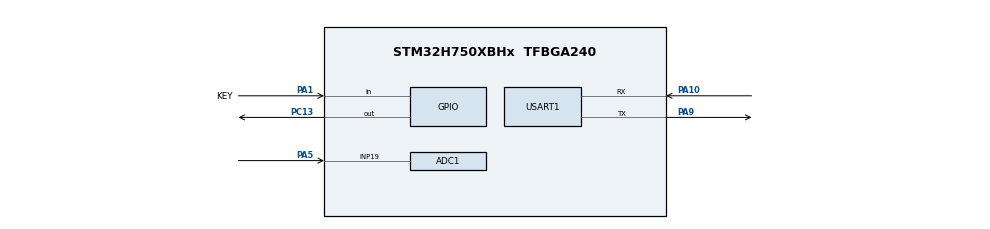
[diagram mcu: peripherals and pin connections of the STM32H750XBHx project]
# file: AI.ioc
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ADC1.Channel-4\#ChannelRegularConversion=ADC_CHANNEL_19
ADC1.NbrOfConversionFlag=1
ADC1.OffsetNumber-4\#ChannelRegularConversion=ADC_OFFSET_NONE
ADC1.OffsetSignedSaturation-4\#ChannelRegularConversion=DISABLE
ADC1.Rank-4\#ChannelRegularConversion=1
ADC1.SamplingTime-4\#ChannelRegularConversion=ADC_SAMPLETIME_1CYCLE_5
ADC1.master=1
CORTEX_M7.CPU_DCache=Enabled
CORTEX_M7.CPU_ICache=Enabled
CORTEX_M7.default_mode_Activation=1
Mcu.Family=STM32H7
Mcu.Name=STM32H750XBHx
Mcu.Package=TFBGA240
NVIC.PriorityGroup=NVIC_PRIORITYGROUP_4
PA1.GPIO_Label=KEY
PA1.GPIO_PuPd=GPIO_PULLDOWN
PA1.Signal=GPIO_Input
PA10.Mode=Asynchronous
PA10.Signal=USART1_RX
PA5.Signal=ADCx_INP19
PA9.GPIO_Speed=GPIO_SPEED_FREQ_HIGH
PA9.Mode=Asynchronous
PA9.Signal=USART1_TX
PC13.Signal=GPIO_Output
PH0-OSC_IN\ (PH0).Mode=HSE-External-Clock-Source
PH0-OSC_IN\ (PH0).Signal=RCC_OSC_IN
ProjectManager.HeapSize=0x4000
ProjectManager.StackSize=0x4000
ProjectManager.TargetToolchain=MDK-ARM V5.32
RCC.ADCCLockSelection=RCC_ADCCLKSOURCE_PLL3
RCC.ADCFreq_Value=32000000
RCC.APB1Freq_Value=120000000
RCC.APB2Freq_Value=120000000
RCC.APB3Freq_Value=120000000
RCC.APB4Freq_Value=120000000
RCC.CortexFreq_Value=480000000
RCC.D1PPRE=RCC_APB3_DIV2
RCC.D2PPRE1=RCC_APB1_DIV2
RCC.D2PPRE2=RCC_APB2_DIV2
RCC.D3PPRE=RCC_APB4_DIV2
RCC.DIVM1=4
RCC.DIVM2=1
RCC.DIVM3=1
RCC.DIVN1=480
RCC.DIVN2=19
RCC.DIVN3=20
RCC.DIVR3=5
RCC.HCLKFreq_Value=240000000
RCC.HPRE=RCC_HCLK_DIV2
RCC.HSE_VALUE=8000000
RCC.PLL3FRACN=0
RCC.PLLFRACN=0
RCC.PLLSourceVirtual=RCC_PLLSOURCE_HSE
RCC.SYSCLKFreq_VALUE=480000000
RCC.SYSCLKSource=RCC_SYSCLKSOURCE_PLLCLK
RCC.USBFreq_Value=480000000
SH.ADCx_INP19.0=ADC1_INP19,IN19-Single-Ended
STMicroelectronics.X-CUBE-AI.10.2.0.ActivationBufferSizeList=4752
STMicroelectronics.X-CUBE-AI.10.2.0.ActivationBuffers=pool0
STMicroelectronics.X-CUBE-AI.10.2.0.ActivationNames=pool0
STMicroelectronics.X-CUBE-AI.10.2.0.ActivationSizes=AI_NETWORK_DATA_ACTIVATION_1_SIZE
STMicroelectronics.X-CUBE-AI.10.2.0.ApplicationCcDeviceJjApplication=ApplicationTemplate
STMicroelectronics.X-CUBE-AI.10.2.0.HeapSize=0x4000
STMicroelectronics.X-CUBE-AI.10.2.0.InternalRamActivationBufferMaxSize=AI_NETWORK_DATA_ACTIVATIONS_SIZE
STMicroelectronics.X-CUBE-AI.10.2.0.LatestDirectoryUsed-3641962debb2109bb404ed91b162e236a1cb7b712d591e769295285bf5952ec8=D\:\\ONEDREIVE\\OneDrive\\Desktop\\Inbox
STMicroelectronics.X-CUBE-AI.10.2.0.MaximumNumberOfInputLayer=1
STMicroelectronics.X-CUBE-AI.10.2.0.MaximumNumberOfOutputLayer=1
STMicroelectronics.X-CUBE-AI.10.2.0.MaximumSizeOfInputLayer=1
STMicroelectronics.X-CUBE-AI.10.2.0.MaximumSizeOfOutputLayer=1
STMicroelectronics.X-CUBE-AI.10.2.0.ModelActualCompression-3641962debb2109bb404ed91b162e236a1cb7b712d591e769295285bf5952ec8=0.0
STMicroelectronics.X-CUBE-AI.10.2.0.ModelCompression-3641962debb2109bb404ed91b162e236a1cb7b712d591e769295285bf5952ec8=None
STMicroelectronics.X-CUBE-AI.10.2.0.ModelFlashOccupation-3641962debb2109bb404ed91b162e236a1cb7b712d591e769295285bf5952ec8=61936
STMicroelectronics.X-CUBE-AI.10.2.0.ModelHashList=3641962debb2109bb404ed91b162e236a1cb7b712d591e769295285bf5952ec8
STMicroelectronics.X-CUBE-AI.10.2.0.ModelKind-3641962debb2109bb404ed91b162e236a1cb7b712d591e769295285bf5952ec8=TFLITE
STMicroelectronics.X-CUBE-AI.10.2.0.ModelMacc-3641962debb2109bb404ed91b162e236a1cb7b712d591e769295285bf5952ec8=12896
STMicroelectronics.X-CUBE-AI.10.2.0.ModelName-3641962debb2109bb404ed91b162e236a1cb7b712d591e769295285bf5952ec8=network
STMicroelectronics.X-CUBE-AI.10.2.0.ModelNameList=network
STMicroelectronics.X-CUBE-AI.10.2.0.ModelRamOccupation-3641962debb2109bb404ed91b162e236a1cb7b712d591e769295285bf5952ec8=4752
STMicroelectronics.X-CUBE-AI.10.2.0.ModelStructureFile-3641962debb2109bb404ed91b162e236a1cb7b712d591e769295285bf5952ec8=D\:\\ONEDREIVE\\OneDrive\\Desktop\\Inbox\\mnist_simple_model.tflite
STMicroelectronics.X-CUBE-AI.10.2.0.ModelType-3641962debb2109bb404ed91b162e236a1cb7b712d591e769295285bf5952ec8=STM32Cube.AI MCU runtime
STMicroelectronics.X-CUBE-AI.10.2.0.ReadyForCodeGeneration=true
STMicroelectronics.X-CUBE-AI.10.2.0.StackSize=0x4000
STMicroelectronics.X-CUBE-AI.10.2.0.WorkingBufferStartAddrList=0xFFFFFFFF
STMicroelectronics.X-CUBE-AI.10.2.0.XAaCUBEAaAICcArtificialOoIntelligenceJjCore=true
STMicroelectronics.X-CUBE-AI.10.2.0.copyWeightToRam=false
STMicroelectronics.X-CUBE-AI.10.2.0.copyWeightToRam-3641962debb2109bb404ed91b162e236a1cb7b712d591e769295285bf5952ec8=false
STMicroelectronics.X-CUBE-AI.10.2.0.customLayerConfigEnabled=false
STMicroelectronics.X-CUBE-AI.10.2.0.customLayerConfigEnabled-3641962debb2109bb404ed91b162e236a1cb7b712d591e769295285bf5952ec8=false
STMicroelectronics.X-CUBE-AI.10.2.0.noOnnxIoTranspose=false
STMicroelectronics.X-CUBE-AI.10.2.0.noOnnxIoTranspose-3641962debb2109bb404ed91b162e236a1cb7b712d591e769295285bf5952ec8=false
STMicroelectronics.X-CUBE-AI.10.2.0.useInputAllocation=true
STMicroelectronics.X-CUBE-AI.10.2.0.useInputAllocation-3641962debb2109bb404ed91b162e236a1cb7b712d591e769295285bf5952ec8=true
STMicroelectronics.X-CUBE-AI.10.2.0.useOutputAllocation=true
STMicroelectronics.X-CUBE-AI.10.2.0.useOutputAllocation-3641962debb2109bb404ed91b162e236a1cb7b712d591e769295285bf5952ec8=true
USART1.VirtualMode-Asynchronous=VM_ASYNC
VP_CRC_VS_CRC.Mode=CRC_Activate
VP_MEMORYMAP_VS_MEMORYMAP.Mode=CurAppReg
VP_STMicroelectronics.X-CUBE-AI_VS_ArtificialOoIntelligenceJjXAaCUBEAaAI_10.2.0.Mode=ArtificialOoIntelligenceJjXAaCUBEAaAI
VP_STMicroelectronics.X-CUBE-AI_VS_DeviceJjApplication_10.2.0.Mode=DeviceJjApplication
board=custom

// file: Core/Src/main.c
/* USER CODE BEGIN Header */
/**
  ******************************************************************************
  * @file           : main.c
  * @brief          : Main program body
  ******************************************************************************
  * @attention
  *
  * Copyright (c) 2026 STMicroelectronics.
  * All rights reserved.
  *
  * This software is licensed under terms that can be found in the LICENSE file
  * in the root directory of this software component.
  * If no LICENSE file comes with this software, it is provided AS-IS.
  *
  ******************************************************************************
  */
/* USER CODE END Header */
#include "main.h"
#include "adc.h"
#include "crc.h"
#include "memorymap.h"
#include "usart.h"
#include "gpio.h"
#include "app_x-cube-ai.h"

/* USER CODE BEGIN Includes */

#include <stdio.h>
/* USER CODE END Includes */

/* USER CODE BEGIN PTD */
#define LED_PIN GPIO_PIN_13
#define LED_GPIO_PORT GPIOC
#define LED_ON  HAL_GPIO_WritePin(LED_GPIO_PORT, LED_PIN, GPIO_PIN_RESET)  // 低电平点亮（根据硬件调整）
#define LED_OFF HAL_GPIO_WritePin(LED_GPIO_PORT, LED_PIN, GPIO_PIN_SET)    // 高电平熄灭
/* USER CODE END PTD */

/* USER CODE BEGIN PV */
int fputc(int ch, FILE *f) {
    extern UART_HandleTypeDef huart1;
    HAL_UART_Transmit(&huart1, (uint8_t *)&ch, 1, 0xFFFF);
    return ch;
}
/* USER CODE END PV */

void SystemClock_Config(void);
static void MPU_Config(void);

int main(void)
{

  /* MPU Configuration--------------------------------------------------------*/
  MPU_Config();

  /* Enable the CPU Cache */

  /* Enable I-Cache---------------------------------------------------------*/
  SCB_EnableICache();

  /* Enable D-Cache---------------------------------------------------------*/
  SCB_EnableDCache();

  /* MCU Configuration--------------------------------------------------------*/

  /* Reset of all peripherals, Initializes the Flash interface and the Systick. */
  HAL_Init();

  /* Configure the system clock */
  SystemClock_Config();

  /* Initialize all configured peripherals */
  MX_GPIO_Init();
  MX_ADC1_Init();
  MX_USART1_UART_Init();
  MX_CRC_Init();
  MX_X_CUBE_AI_Init();
  /* USER CODE BEGIN 2 */
HAL_GPIO_WritePin(GPIOC, GPIO_PIN_13, GPIO_PIN_RESET);
  /* USER CODE END 2 */

  /* Infinite loop */
  while (1)
  {

MX_X_CUBE_AI_Process();

  }
}

void SystemClock_Config(void)
{
  RCC_OscInitTypeDef RCC_OscInitStruct = {0};
  RCC_ClkInitTypeDef RCC_ClkInitStruct = {0};

  /** Supply configuration update enable
  */
  HAL_PWREx_ConfigSupply(PWR_LDO_SUPPLY);

  /** Configure the main internal regulator output voltage
  */
  __HAL_PWR_VOLTAGESCALING_CONFIG(PWR_REGULATOR_VOLTAGE_SCALE0);

  while(!__HAL_PWR_GET_FLAG(PWR_FLAG_VOSRDY)) {}

  /** Initializes the RCC Oscillators according to the specified parameters
  * in the RCC_OscInitTypeDef structure.
  */
  RCC_OscInitStruct.OscillatorType = RCC_OSCILLATORTYPE_HSE;
  RCC_OscInitStruct.HSEState = RCC_HSE_BYPASS;
  RCC_OscInitStruct.PLL.PLLState = RCC_PLL_ON;
  RCC_OscInitStruct.PLL.PLLSource = RCC_PLLSOURCE_HSE;
  RCC_OscInitStruct.PLL.PLLM = 4;
  RCC_OscInitStruct.PLL.PLLN = 480;
  RCC_OscInitStruct.PLL.PLLP = 2;
  RCC_OscInitStruct.PLL.PLLQ = 2;
  RCC_OscInitStruct.PLL.PLLR = 2;
  RCC_OscInitStruct.PLL.PLLRGE = RCC_PLL1VCIRANGE_1;
  RCC_OscInitStruct.PLL.PLLVCOSEL = RCC_PLL1VCOWIDE;
  RCC_OscInitStruct.PLL.PLLFRACN = 0;
  if (HAL_RCC_OscConfig(&RCC_OscInitStruct) != HAL_OK)
  {
    Error_Handler();
  }

  /** Initializes the CPU, AHB and APB buses clocks
  */
  RCC_ClkInitStruct.ClockType = RCC_CLOCKTYPE_HCLK|RCC_CLOCKTYPE_SYSCLK
                              |RCC_CLOCKTYPE_PCLK1|RCC_CLOCKTYPE_PCLK2
                              |RCC_CLOCKTYPE_D3PCLK1|RCC_CLOCKTYPE_D1PCLK1;
  RCC_ClkInitStruct.SYSCLKSource = RCC_SYSCLKSOURCE_PLLCLK;
  RCC_ClkInitStruct.SYSCLKDivider = RCC_SYSCLK_DIV1;
  RCC_ClkInitStruct.AHBCLKDivider = RCC_HCLK_DIV2;
  RCC_ClkInitStruct.APB3CLKDivider = RCC_APB3_DIV2;
  RCC_ClkInitStruct.APB1CLKDivider = RCC_APB1_DIV2;
  RCC_ClkInitStruct.APB2CLKDivider = RCC_APB2_DIV2;
  RCC_ClkInitStruct.APB4CLKDivider = RCC_APB4_DIV2;

  if (HAL_RCC_ClockConfig(&RCC_ClkInitStruct, FLASH_LATENCY_4) != HAL_OK)
  {
    Error_Handler();
  }
}

 /* MPU Configuration */

void MPU_Config(void)
{
  MPU_Region_InitTypeDef MPU_InitStruct = {0};

  /* Disables the MPU */
  HAL_MPU_Disable();

  /** Initializes and configures the Region and the memory to be protected
  */
  MPU_InitStruct.Enable = MPU_REGION_ENABLE;
  MPU_InitStruct.Number = MPU_REGION_NUMBER0;
  MPU_InitStruct.BaseAddress = 0x0;
  MPU_InitStruct.Size = MPU_REGION_SIZE_4GB;
  MPU_InitStruct.SubRegionDisable = 0x87;
  MPU_InitStruct.TypeExtField = MPU_TEX_LEVEL0;
  MPU_InitStruct.AccessPermission = MPU_REGION_NO_ACCESS;
  MPU_InitStruct.DisableExec = MPU_INSTRUCTION_ACCESS_DISABLE;
  MPU_InitStruct.IsShareable = MPU_ACCESS_SHAREABLE;
  MPU_InitStruct.IsCacheable = MPU_ACCESS_NOT_CACHEABLE;
  MPU_InitStruct.IsBufferable = MPU_ACCESS_NOT_BUFFERABLE;

  HAL_MPU_ConfigRegion(&MPU_InitStruct);
  /* Enables the MPU */
  HAL_MPU_Enable(MPU_PRIVILEGED_DEFAULT);

}

void Error_Handler(void)
{
  __disable_irq();
  while (1)
  {
  }
}
